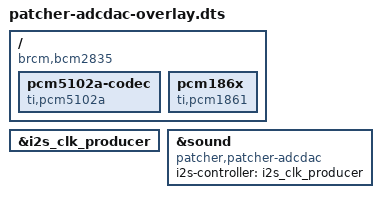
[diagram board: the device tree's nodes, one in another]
// Definitions for Patcher ADCDAC
/dts-v1/;
/plugin/;

/ {
	compatible = "brcm,bcm2835";

	fragment@0 {
		target = <&i2s_clk_producer>;
		__overlay__ {
			status = "okay";
		};
	};

	fragment@1 {
		target-path = "/";
		__overlay__ {
			pcm5102a-codec {
				#sound-dai-cells = <0>;
				compatible = "ti,pcm5102a";
				status = "okay";
			};
		};
	};

	fragment@2 {
		target = <&sound>;
		__overlay__ {
			compatible = "patcher,patcher-adcdac";
			i2s-controller = <&i2s_clk_producer>;
			status = "okay";
		};
	};
};



//------------------

/dts-v1/;
/plugin/;

/ {
    compatible = "brcm,bcm2835";

    fragment@0 {
        target = <&i2s_clk_producer>;
        __overlay__ {
            status = "okay";
        };
    };

    fragment@1 {
        target_path = "/";
        __overlay__ {
            pcm5102a-codec {
                #sound-dai-cells = <0>;
                compatible = "ti,pcm5102a";
                status = "okay";
            };

            pcm186x {
                #sound-dai-cells = <0>;
                compatible = "ti,pcm1861";
                status = "okay";
            };
        };
    };

    fragment@2 {
        target = <&sound>;
        __overlay__ {
            compatible = "patcher,patcher-adcdac";
            i2s-controller = <&i2s_clk_producer>;
            status = "okay";
        };
    };
};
